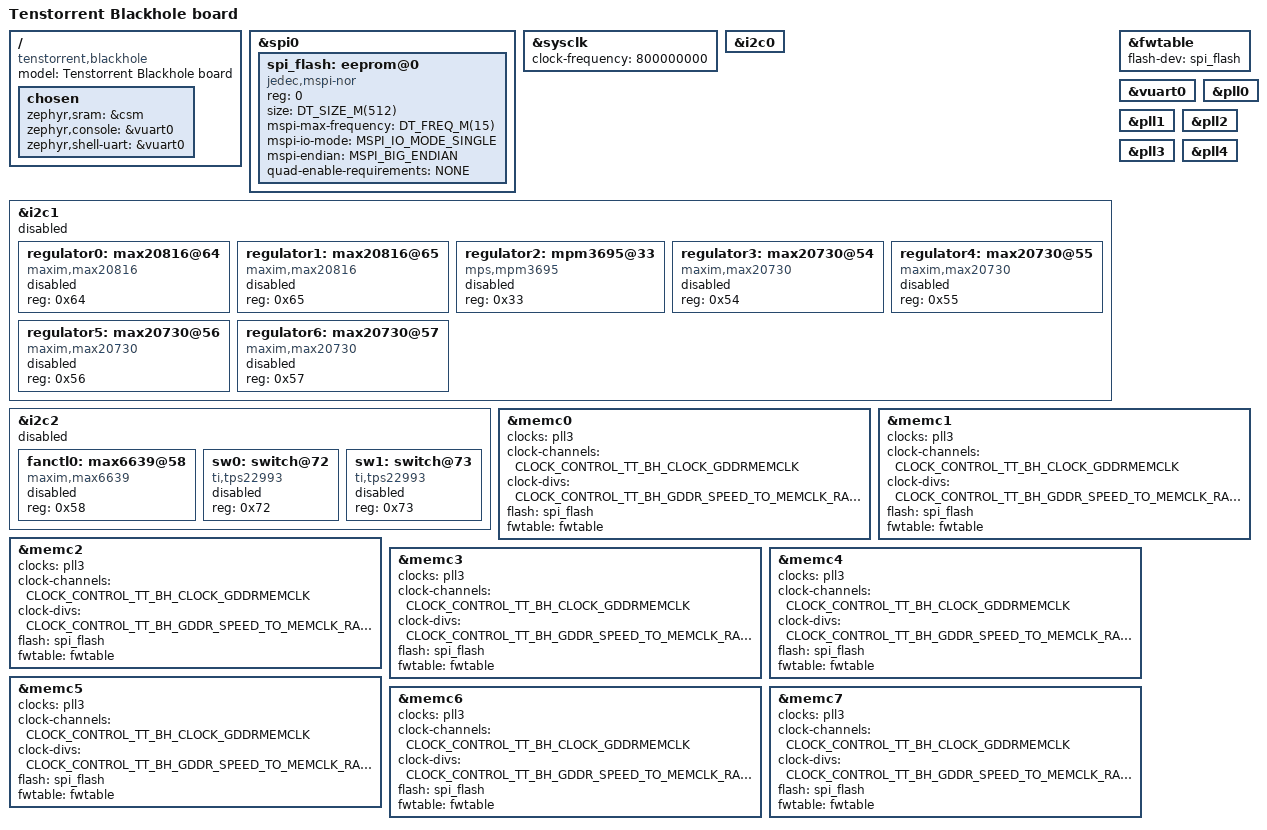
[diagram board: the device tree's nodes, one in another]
/*
 * Copyright (c) 2024 Tenstorrent AI ULC
 * SPDX-License-Identifier: Apache-2.0
 */

/dts-v1/;

#include <arc/tenstorrent/tt_blackhole_smc.dtsi>
#include <zephyr/dt-bindings/clock_control/clock_control_tt_bh.h>
#include "tt_blackhole_smc-pinctrl.dtsi"

#include <freq.h>
#include <mem.h>

/ {
	model = "Tenstorrent Blackhole board";
	compatible = "tenstorrent,blackhole";

	chosen {
		zephyr,sram = &csm;
		zephyr,console = &vuart0;
		zephyr,shell-uart = &vuart0;
	};
};

&spi0 {
	status = "okay";

	spi_flash: eeprom@0 {
		compatible = "jedec,mspi-nor";
		reg = <0>;
		status = "okay";
		/* Programming has experimentally been reliable up to 17 MHz, use 15 to be safe */
		size = <DT_SIZE_M(512)>;
		mspi-max-frequency = <DT_FREQ_M(15)>;
		mspi-io-mode = "MSPI_IO_MODE_SINGLE";
		mspi-endian = "MSPI_BIG_ENDIAN";
		quad-enable-requirements = "NONE";
	};
};

/* BH_ARC PLL library will raise system clock to 800MHz */
&sysclk {
	clock-frequency = <800000000>;
};

&i2c0 {
	status = "okay";
};

&i2c1 {
	status = "disabled";

	regulator0: max20816@64 {
		compatible = "maxim,max20816";
		reg = <0x64>;
		status = "disabled";
	};

	regulator1: max20816@65 {
		compatible = "maxim,max20816";
		reg = <0x65>;
		status = "disabled";
	};

	regulator2: mpm3695@33 {
		compatible = "mps,mpm3695";
		reg = <0x33>;
		status = "disabled";
	};

	regulator3: max20730@54 {
		compatible = "maxim,max20730";
		reg = <0x54>;
		status = "disabled";
	};

	regulator4: max20730@55 {
		compatible = "maxim,max20730";
		reg = <0x55>;
		status = "disabled";
	};

	regulator5: max20730@56 {
		compatible = "maxim,max20730";
		reg = <0x56>;
		status = "disabled";
	};

	regulator6: max20730@57 {
		compatible = "maxim,max20730";
		reg = <0x57>;
		status = "disabled";
	};
};

&i2c2 {
	status = "disabled";

	fanctl0: max6639@58 {
		compatible = "maxim,max6639";
		reg = <0x58>;
		status = "disabled";
	};

	sw0: switch@72 {
		compatible = "ti,tps22993";
		reg = <0x72>;
		status = "disabled";
	};

	sw1: switch@73 {
		compatible = "ti,tps22993";
		reg = <0x73>;
		status = "disabled";
	};
};

&fwtable {
	flash-dev = <&spi_flash>;
	status = "okay";
};

&vuart0 {
	status = "okay";
};

&pll0{
	status = "okay";
};

&pll1 {
	status = "okay";
};

&pll2 {
	status = "okay";
};

&pll3 {
	status = "okay";
};

&pll4 {
	status = "okay";
};

&spi_flash {
	#include "tt_blackhole_fixed_partitions.dtsi"
};

&memc0 {
	clocks = <&pll3>;
	clock-channels = <CLOCK_CONTROL_TT_BH_CLOCK_GDDRMEMCLK>;
	clock-divs = <CLOCK_CONTROL_TT_BH_GDDR_SPEED_TO_MEMCLK_RATIO>;
	flash = <&spi_flash>;
	fwtable = <&fwtable>;
	status = "okay";
};

&memc1 {
	clocks = <&pll3>;
	clock-channels = <CLOCK_CONTROL_TT_BH_CLOCK_GDDRMEMCLK>;
	clock-divs = <CLOCK_CONTROL_TT_BH_GDDR_SPEED_TO_MEMCLK_RATIO>;
	flash = <&spi_flash>;
	fwtable = <&fwtable>;
	status = "okay";
};

&memc2 {
	clocks = <&pll3>;
	clock-channels = <CLOCK_CONTROL_TT_BH_CLOCK_GDDRMEMCLK>;
	clock-divs = <CLOCK_CONTROL_TT_BH_GDDR_SPEED_TO_MEMCLK_RATIO>;
	flash = <&spi_flash>;
	fwtable = <&fwtable>;
	status = "okay";
};

&memc3 {
	clocks = <&pll3>;
	clock-channels = <CLOCK_CONTROL_TT_BH_CLOCK_GDDRMEMCLK>;
	clock-divs = <CLOCK_CONTROL_TT_BH_GDDR_SPEED_TO_MEMCLK_RATIO>;
	flash = <&spi_flash>;
	fwtable = <&fwtable>;
	status = "okay";
};

&memc4 {
	clocks = <&pll3>;
	clock-channels = <CLOCK_CONTROL_TT_BH_CLOCK_GDDRMEMCLK>;
	clock-divs = <CLOCK_CONTROL_TT_BH_GDDR_SPEED_TO_MEMCLK_RATIO>;
	flash = <&spi_flash>;
	fwtable = <&fwtable>;
	status = "okay";
};

&memc5 {
	clocks = <&pll3>;
	clock-channels = <CLOCK_CONTROL_TT_BH_CLOCK_GDDRMEMCLK>;
	clock-divs = <CLOCK_CONTROL_TT_BH_GDDR_SPEED_TO_MEMCLK_RATIO>;
	flash = <&spi_flash>;
	fwtable = <&fwtable>;
	status = "okay";
};

&memc6 {
	clocks = <&pll3>;
	clock-channels = <CLOCK_CONTROL_TT_BH_CLOCK_GDDRMEMCLK>;
	clock-divs = <CLOCK_CONTROL_TT_BH_GDDR_SPEED_TO_MEMCLK_RATIO>;
	flash = <&spi_flash>;
	fwtable = <&fwtable>;
	status = "okay";
};

&memc7 {
	clocks = <&pll3>;
	clock-channels = <CLOCK_CONTROL_TT_BH_CLOCK_GDDRMEMCLK>;
	clock-divs = <CLOCK_CONTROL_TT_BH_GDDR_SPEED_TO_MEMCLK_RATIO>;
	flash = <&spi_flash>;
	fwtable = <&fwtable>;
	status = "okay";
};
